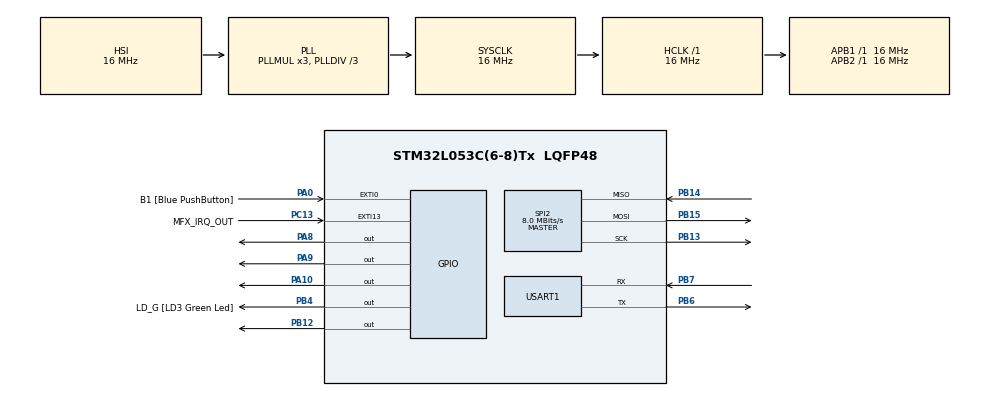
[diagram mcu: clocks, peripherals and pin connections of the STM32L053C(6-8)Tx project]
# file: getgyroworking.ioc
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Mcu.Family=STM32L0
Mcu.Name=STM32L053C(6-8)Tx
Mcu.Package=LQFP48
PA0.GPIO_Label=B1 [Blue PushButton]
PA0.GPIO_ModeDefaultEXTI=GPIO_MODE_EVT_RISING
PA0.GPIO_PuPd=GPIO_NOPULL
PA0.Signal=GPXTI0
PA10.Signal=GPIO_Output
PA13.GPIO_Label=SWDIO
PA13.Signal=SYS_SWDIO
PA8.Signal=GPIO_Output
PA9.Signal=GPIO_Output
PB12.Signal=GPIO_Output
PB13.Mode=Full_Duplex_Master
PB13.Signal=SPI2_SCK
PB14.Mode=Full_Duplex_Master
PB14.Signal=SPI2_MISO
PB15.Mode=Full_Duplex_Master
PB15.Signal=SPI2_MOSI
PB4.GPIO_Label=LD_G [LD3 Green Led]
PB4.GPIO_ModeDefaultOutputPP=GPIO_MODE_OUTPUT_PP
PB4.GPIO_PuPd=GPIO_NOPULL
PB4.GPIO_Speed=GPIO_SPEED_FREQ_LOW
PB4.Signal=GPIO_Output
PB6.Mode=Asynchronous
PB6.Signal=USART1_TX
PB7.Mode=Asynchronous
PB7.Signal=USART1_RX
PB8.GPIO_Label=MFX_I2C_SCL
PB8.Signal=I2C1_SCL
PB9.GPIO_Label=MFX_I2C_SDA
PB9.Signal=I2C1_SDA
PC13.GPIO_Label=MFX_IRQ_OUT
PC13.Signal=GPXTI13
PC14-OSC32_IN.GPIO_Label=PC14-OSC32_IN
PC14-OSC32_IN.Signal=RCC_OSC32_IN
PC15-OSC32_OUT.GPIO_Label=PC15-OSC32_OUT
PC15-OSC32_OUT.Signal=RCC_OSC32_OUT
PH0-OSC_IN.GPIO_Label=MCO
PH0-OSC_IN.Signal=RCC_OSC_IN
ProjectManager.HeapSize=0x200
ProjectManager.StackSize=0x400
ProjectManager.TargetToolchain=SW4STM32
RCC.AHBFreq_Value=16000000
RCC.APB1Freq_Value=16000000
RCC.APB1TimFreq_Value=16000000
RCC.APB2Freq_Value=16000000
RCC.APB2TimFreq_Value=16000000
RCC.HCLKFreq_Value=16000000
RCC.HSE_VALUE=8000000
RCC.HSI16_VALUE=16000000
RCC.HSI48MClockSelection=RCC_USBCLKSOURCE_HSI48
RCC.HSI48_VALUE=48000000
RCC.HSI_VALUE=16000000
RCC.LSE_VALUE=32768
RCC.MSI_VALUE=2097000
RCC.PLLDIV=RCC_PLLDIV_3
RCC.RTCClockSelectionVirtual=RCC_RTCCLKSOURCE_LSE
RCC.SYSCLKFreq_VALUE=16000000
RCC.SYSCLKSource=RCC_SYSCLKSOURCE_PLLCLK
RCC.VCOOutputFreq_Value=48000000
SPI2.CalculateBaudRate=8.0 MBits/s
SPI2.Direction=SPI_DIRECTION_2LINES
SPI2.Mode=SPI_MODE_MASTER
SPI2.VirtualType=VM_MASTER
USART1.VirtualMode-Asynchronous=VM_ASYNC
board=STM32L0538-DISCO

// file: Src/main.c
/* USER CODE BEGIN Header */
/**
  ******************************************************************************
  * @file           : main.c
  * @brief          : Main program body
  ******************************************************************************
  * @attention
  *
  * <h2><center>&copy; Copyright (c) 2019 STMicroelectronics.
  * All rights reserved.</center></h2>
  *
  * This software component is licensed by ST under BSD 3-Clause license,
  * the "License"; You may not use this file except in compliance with the
  * License. You may obtain a copy of the License at:
  *                        opensource.org/licenses/BSD-3-Clause
  *
  ******************************************************************************
  */
/* USER CODE END Header */

#include "main.h"
#include "lsm6dsl.h"

SPI_HandleTypeDef hspi2;

UART_HandleTypeDef huart1;

void SystemClock_Config(void);
static void MX_GPIO_Init(void);
static void MX_SPI2_Init(void);
static void MX_USART1_UART_Init(void);
void updateMaxValues(float max[], float current[]);

int main(void)
{
	int ret = 0;
	char  dataOut[100];
	uint8_t i = 0;
	float maxAcc[3] = {0,0,0};//x,y,z
	float maxGyro[3] = {0,0,0};
	float currentAcc[3] = {0,0,0};
	float currentGyro[3] = {0,0,0};

  /* MCU Configuration--------------------------------------------------------*/

  /* Reset of all peripherals, Initializes the Flash interface and the Systick. */
  HAL_Init();

  /* Configure the system clock */
  SystemClock_Config();

  /* Initialize all configured peripherals */
  MX_GPIO_Init();
  MX_SPI2_Init();
  MX_USART1_UART_Init();

  ret = GYRO_INIT(hspi2);

  /* USER CODE BEGIN 2 */
  if (ret > 0)
	    HAL_GPIO_WritePin(GPIOA, GPIO_PIN_10, GPIO_PIN_SET);

  /* USER CODE END 2 */

  /* Infinite loop */
  while (1)
  {

  /* USER CODE END WHILE */
	 // ret = lsm6dsl_gyro_get_raw_x(hspi2);
	 currentAcc[0] = readFloatAccelX(hspi2);
	  currentAcc[1] = readFloatAccelY(hspi2);
	  currentAcc[2] = readFloatAccelZ(hspi2);

//	  (void)snprintf(dataOut, 80, "ACC X: %f , Y: %f , Z: %f \r\n",currentAcc[0],currentAcc[1],currentAcc[2] );
//	HAL_UART_Transmit(&huart1, dataOut,50 ,50);

	currentGyro[0] = readFloatGyroX(hspi2);
	currentGyro[1] = readFloatGyroY(hspi2);
	currentGyro[2] = readFloatGyroZ(hspi2);

//	  (void)snprintf(dataOut, 80, "GYRO X: %f , Y: %f, Z: %f \r\n",currentGyro[0],currentGyro[1],currentGyro[2] );
//	HAL_UART_Transmit(&huart1, dataOut,50 ,50);

	updateMaxValues(&maxAcc,&currentAcc);
	updateMaxValues(&maxGyro,&currentGyro);

	(void)snprintf(dataOut, 80, "ACC X: %f , Y: %f , Z: %f \r\n",maxAcc[0],maxAcc[1],maxAcc[2] );
	HAL_UART_Transmit(&huart1, dataOut,50 ,50);

	for(i = 0; i < 3; i ++)
	{
		if (currentAcc[i] > maxAcc[i])
			maxAcc[i] = currentAcc[i];
	}

	//ret = ret - 1;
	//  if (ret == 0x6A)
	//	    HAL_GPIO_WritePin(GPIOA, GPIO_PIN_10, GPIO_PIN_SET);
	//  else
//		    HAL_GPIO_WritePin(GPIOA, GPIO_PIN_10, GPIO_PIN_RESET);
	 //asdf HAL_Delay(100);

	  HAL_GPIO_WritePin(GPIOA, GPIO_PIN_9, GPIO_PIN_SET);
	    HAL_GPIO_WritePin(GPIOA, GPIO_PIN_10, GPIO_PIN_RESET);
	    HAL_Delay(100);
	    HAL_GPIO_WritePin(GPIOA, GPIO_PIN_9, GPIO_PIN_RESET);
	    HAL_GPIO_WritePin(GPIOA, GPIO_PIN_10, GPIO_PIN_SET);

	  HAL_Delay(100);
  }
}
void updateMaxValues(float max[], float current[])
{
	uint8_t i;
	for(i = 0; i < 3; i ++)
	{
		if (current[i] > max[i])
			max[i] = current[i];
	}
}

void SystemClock_Config(void)
{
  RCC_OscInitTypeDef RCC_OscInitStruct = {0};
  RCC_ClkInitTypeDef RCC_ClkInitStruct = {0};
  RCC_PeriphCLKInitTypeDef PeriphClkInit = {0};

  /** Configure the main internal regulator output voltage
  */
  __HAL_PWR_VOLTAGESCALING_CONFIG(PWR_REGULATOR_VOLTAGE_SCALE1);
  /** Initializes the CPU, AHB and APB busses clocks
  */
  RCC_OscInitStruct.OscillatorType = RCC_OSCILLATORTYPE_HSI;
  RCC_OscInitStruct.HSIState = RCC_HSI_ON;
  RCC_OscInitStruct.HSICalibrationValue = RCC_HSICALIBRATION_DEFAULT;
  RCC_OscInitStruct.PLL.PLLState = RCC_PLL_ON;
  RCC_OscInitStruct.PLL.PLLSource = RCC_PLLSOURCE_HSI;
  RCC_OscInitStruct.PLL.PLLMUL = RCC_PLLMUL_3;
  RCC_OscInitStruct.PLL.PLLDIV = RCC_PLLDIV_3;
  if (HAL_RCC_OscConfig(&RCC_OscInitStruct) != HAL_OK)
  {
    Error_Handler();
  }
  /** Initializes the CPU, AHB and APB busses clocks
  */
  RCC_ClkInitStruct.ClockType = RCC_CLOCKTYPE_HCLK|RCC_CLOCKTYPE_SYSCLK
                              |RCC_CLOCKTYPE_PCLK1|RCC_CLOCKTYPE_PCLK2;
  RCC_ClkInitStruct.SYSCLKSource = RCC_SYSCLKSOURCE_PLLCLK;
  RCC_ClkInitStruct.AHBCLKDivider = RCC_SYSCLK_DIV1;
  RCC_ClkInitStruct.APB1CLKDivider = RCC_HCLK_DIV1;
  RCC_ClkInitStruct.APB2CLKDivider = RCC_HCLK_DIV1;

  if (HAL_RCC_ClockConfig(&RCC_ClkInitStruct, FLASH_LATENCY_0) != HAL_OK)
  {
    Error_Handler();
  }
  PeriphClkInit.PeriphClockSelection = RCC_PERIPHCLK_USART1;
  PeriphClkInit.Usart1ClockSelection = RCC_USART1CLKSOURCE_PCLK2;
  if (HAL_RCCEx_PeriphCLKConfig(&PeriphClkInit) != HAL_OK)
  {
    Error_Handler();
  }
}

static void MX_SPI2_Init(void)
{

  /* SPI2 parameter configuration*/
  hspi2.Instance = SPI2;
  hspi2.Init.Mode = SPI_MODE_MASTER;
  hspi2.Init.Direction = SPI_DIRECTION_2LINES;
  hspi2.Init.DataSize = SPI_DATASIZE_8BIT;
  hspi2.Init.CLKPolarity = SPI_POLARITY_LOW;
  hspi2.Init.CLKPhase = SPI_PHASE_1EDGE;
  hspi2.Init.NSS = SPI_NSS_SOFT;
  hspi2.Init.BaudRatePrescaler = SPI_BAUDRATEPRESCALER_2;
  hspi2.Init.FirstBit = SPI_FIRSTBIT_MSB;
  hspi2.Init.TIMode = SPI_TIMODE_DISABLE;
  hspi2.Init.CRCCalculation = SPI_CRCCALCULATION_DISABLE;
  hspi2.Init.CRCPolynomial = 7;
  if (HAL_SPI_Init(&hspi2) != HAL_OK)
  {
    Error_Handler();
  }

}

static void MX_USART1_UART_Init(void)
{

  huart1.Instance = USART1;
  huart1.Init.BaudRate = 115200;
  huart1.Init.WordLength = UART_WORDLENGTH_8B;
  huart1.Init.StopBits = UART_STOPBITS_1;
  huart1.Init.Parity = UART_PARITY_NONE;
  huart1.Init.Mode = UART_MODE_TX_RX;
  huart1.Init.HwFlowCtl = UART_HWCONTROL_NONE;
  huart1.Init.OverSampling = UART_OVERSAMPLING_16;
  huart1.Init.OneBitSampling = UART_ONE_BIT_SAMPLE_DISABLE;
  huart1.AdvancedInit.AdvFeatureInit = UART_ADVFEATURE_NO_INIT;
  if (HAL_UART_Init(&huart1) != HAL_OK)
  {
    Error_Handler();
  }

}

static void MX_GPIO_Init(void)
{
  GPIO_InitTypeDef GPIO_InitStruct = {0};

  /* GPIO Ports Clock Enable */
  __HAL_RCC_GPIOC_CLK_ENABLE();
  __HAL_RCC_GPIOH_CLK_ENABLE();
  __HAL_RCC_GPIOA_CLK_ENABLE();
  __HAL_RCC_GPIOB_CLK_ENABLE();

  /*Configure GPIO pin Output Level */
  HAL_GPIO_WritePin(GPIOB, GPIO_PIN_12|LD_G_Pin, GPIO_PIN_RESET);

  /*Configure GPIO pin Output Level */
  HAL_GPIO_WritePin(GPIOA, GPIO_PIN_8|GPIO_PIN_9|GPIO_PIN_10, GPIO_PIN_RESET);

  /*Configure GPIO pin : MFX_IRQ_OUT_Pin */
  GPIO_InitStruct.Pin = MFX_IRQ_OUT_Pin;
  GPIO_InitStruct.Mode = GPIO_MODE_IT_RISING;
  GPIO_InitStruct.Pull = GPIO_NOPULL;
  HAL_GPIO_Init(MFX_IRQ_OUT_GPIO_Port, &GPIO_InitStruct);

  /*Configure GPIO pin : B1_Pin */
  GPIO_InitStruct.Pin = B1_Pin;
  GPIO_InitStruct.Mode = GPIO_MODE_EVT_RISING;
  GPIO_InitStruct.Pull = GPIO_NOPULL;
  HAL_GPIO_Init(B1_GPIO_Port, &GPIO_InitStruct);

  /*Configure GPIO pins : PB12 LD_G_Pin */
  GPIO_InitStruct.Pin = GPIO_PIN_12|LD_G_Pin;
  GPIO_InitStruct.Mode = GPIO_MODE_OUTPUT_PP;
  GPIO_InitStruct.Pull = GPIO_NOPULL;
  GPIO_InitStruct.Speed = GPIO_SPEED_FREQ_LOW;
  HAL_GPIO_Init(GPIOB, &GPIO_InitStruct);

  /*Configure GPIO pins : PA8 PA9 PA10 */
  GPIO_InitStruct.Pin = GPIO_PIN_8|GPIO_PIN_9|GPIO_PIN_10;
  GPIO_InitStruct.Mode = GPIO_MODE_OUTPUT_PP;
  GPIO_InitStruct.Pull = GPIO_NOPULL;
  GPIO_InitStruct.Speed = GPIO_SPEED_FREQ_LOW;
  HAL_GPIO_Init(GPIOA, &GPIO_InitStruct);

  /*Configure GPIO pins : MFX_I2C_SCL_Pin MFX_I2C_SDA_Pin */
  GPIO_InitStruct.Pin = MFX_I2C_SCL_Pin|MFX_I2C_SDA_Pin;
  GPIO_InitStruct.Mode = GPIO_MODE_AF_OD;
  GPIO_InitStruct.Pull = GPIO_PULLUP;
  GPIO_InitStruct.Speed = GPIO_SPEED_FREQ_VERY_HIGH;
  GPIO_InitStruct.Alternate = GPIO_AF4_I2C1;
  HAL_GPIO_Init(GPIOB, &GPIO_InitStruct);

}

void Error_Handler(void)
{
}

/************************ (C) COPYRIGHT STMicroelectronics *****END OF FILE****/
